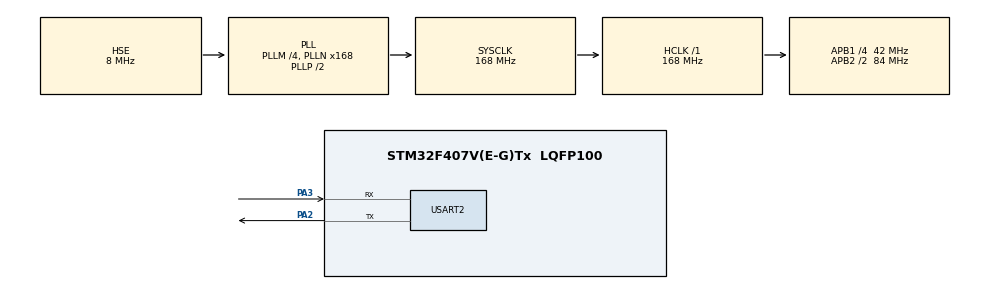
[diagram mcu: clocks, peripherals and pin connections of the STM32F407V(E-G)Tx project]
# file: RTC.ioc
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Mcu.Family=STM32F4
Mcu.Name=STM32F407V(E-G)Tx
Mcu.Package=LQFP100
NVIC.PriorityGroup=NVIC_PRIORITYGROUP_4
NVIC.RTC_Alarm_IRQn=true\:0\:0\:false\:false\:true\:true\:true
PA13.Mode=Serial_Wire
PA13.Signal=SYS_JTMS-SWDIO
PA14.Mode=Serial_Wire
PA14.Signal=SYS_JTCK-SWCLK
PA2.Mode=Asynchronous
PA2.Signal=USART2_TX
PA3.Mode=Asynchronous
PA3.Signal=USART2_RX
PC14-OSC32_IN.Mode=LSE-External-Oscillator
PC14-OSC32_IN.Signal=RCC_OSC32_IN
PC15-OSC32_OUT.Mode=LSE-External-Oscillator
PC15-OSC32_OUT.Signal=RCC_OSC32_OUT
PH0-OSC_IN.Mode=HSE-External-Oscillator
PH0-OSC_IN.Signal=RCC_OSC_IN
PH1-OSC_OUT.Mode=HSE-External-Oscillator
PH1-OSC_OUT.Signal=RCC_OSC_OUT
ProjectManager.HeapSize=0x200
ProjectManager.StackSize=0x400
ProjectManager.TargetToolchain=STM32CubeIDE
RCC.48MHZClocksFreq_Value=84000000
RCC.AHBFreq_Value=168000000
RCC.APB1CLKDivider=RCC_HCLK_DIV4
RCC.APB1Freq_Value=42000000
RCC.APB1TimFreq_Value=84000000
RCC.APB2CLKDivider=RCC_HCLK_DIV2
RCC.APB2Freq_Value=84000000
RCC.APB2TimFreq_Value=168000000
RCC.CortexFreq_Value=168000000
RCC.HCLKFreq_Value=168000000
RCC.HSE_VALUE=8000000
RCC.HSI_VALUE=16000000
RCC.PLLM=4
RCC.PLLN=168
RCC.PLLSourceVirtual=RCC_PLLSOURCE_HSE
RCC.SYSCLKFreq_VALUE=168000000
RCC.SYSCLKSource=RCC_SYSCLKSOURCE_PLLCLK
RCC.VCOOutputFreq_Value=336000000
RTC.Alarm=RTC_ALARM_A
RTC.AlarmMaskDateWeekDay=RTC_ALARMMASK_DATEWEEKDAY
RTC.AsynchPrediv=127
RTC.Date=21
RTC.Format=RTC_FORMAT_BIN
RTC.Hours=18
RTC.Hours_A=18
RTC.Minutes=15
RTC.Minutes_A=16
RTC.Month=RTC_MONTH_OCTOBER
RTC.Seconds=50
RTC.Seconds_A=5
RTC.SynchPrediv=256
RTC.WeekDay=RTC_WEEKDAY_THURSDAY
RTC.Year=21
USART2.VirtualMode=VM_ASYNC
VP_RTC_VS_RTC_Activate.Mode=RTC_Enabled
VP_RTC_VS_RTC_Alarm_A_Intern.Mode=Alarm A
VP_RTC_VS_RTC_Calendar.Mode=RTC_Calendar
board=custom

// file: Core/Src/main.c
/* USER CODE BEGIN Header */
/**
  ******************************************************************************
  * @file           : main.c
  * @brief          : Main program body
  ******************************************************************************
  * @attention
  *
  * <h2><center>&copy; Copyright (c) 2021 STMicroelectronics.
  * All rights reserved.</center></h2>
  *
  * This software component is licensed by ST under BSD 3-Clause license,
  * the "License"; You may not use this file except in compliance with the
  * License. You may obtain a copy of the License at:
  *                        opensource.org/licenses/BSD-3-Clause
  *
  ******************************************************************************
  */
/* USER CODE END Header */
#include "main.h"

/* USER CODE BEGIN Includes */
#include "stdio.h"
#include "string.h"
/* USER CODE END Includes */

RTC_HandleTypeDef hrtc;

UART_HandleTypeDef huart2;

/* USER CODE BEGIN PV */
RTC_TimeTypeDef sTime = {0};
RTC_DateTypeDef DateToUpdate = {0};
RTC_AlarmTypeDef sAlarm = {0}; // структура будильника

char trans_str[64] = {0,};
/* USER CODE END PV */

void SystemClock_Config(void);
static void MX_GPIO_Init(void);
static void MX_RTC_Init(void);
static void MX_USART2_UART_Init(void);

/* USER CODE BEGIN 0 */
void HAL_RTC_AlarmAEventCallback(RTC_HandleTypeDef *hrtc)
{
        snprintf(trans_str, 63, "Alarm_A\n");
        HAL_UART_Transmit(&huart2, (uint8_t*)trans_str, strlen(trans_str), 1000);
}
/* USER CODE END 0 */

int main(void)
{

  /* MCU Configuration--------------------------------------------------------*/

  /* Reset of all peripherals, Initializes the Flash interface and the Systick. */
  HAL_Init();

  /* Configure the system clock */
  SystemClock_Config();

  /* Initialize all configured peripherals */
  MX_GPIO_Init();
  MX_RTC_Init();
  MX_USART2_UART_Init();

  /* Infinite loop */
  while (1)
  {

    /* USER CODE BEGIN 3 */
      HAL_RTC_GetTime(&hrtc, &sTime, RTC_FORMAT_BIN); // RTC_FORMAT_BIN , RTC_FORMAT_BCD
      snprintf(trans_str, 63, "Time %d:%d:%d\n", sTime.Hours, sTime.Minutes, sTime.Seconds);
      //snprintf(trans_str, 63, "Time %d:%d:%d:%lu\n", sTime.Hours, sTime.Minutes, sTime.Seconds, sTime.SubSeconds);
      HAL_UART_Transmit(&huart2, (uint8_t*)trans_str, strlen(trans_str), 1000);

      HAL_RTC_GetDate(&hrtc, &DateToUpdate, RTC_FORMAT_BIN);
      snprintf(trans_str, 63, "Date %d-%d-20%d\n", DateToUpdate.Date, DateToUpdate.Month, DateToUpdate.Year);
      HAL_UART_Transmit(&huart2, (uint8_t*)trans_str, strlen(trans_str), 1000);

      HAL_RTC_GetAlarm(&hrtc, &sAlarm, RTC_ALARM_A, RTC_FORMAT_BIN);
      snprintf(trans_str, 63, "Settings of alarm %d:%d:%d\n", sAlarm.AlarmTime.Hours, sAlarm.AlarmTime.Minutes, sAlarm.AlarmTime.Seconds);
      HAL_UART_Transmit(&huart2, (uint8_t*)trans_str, strlen(trans_str), 1000);

      HAL_Delay(1000);

  }
  /* USER CODE END 3 */
}

void SystemClock_Config(void)
{
  RCC_OscInitTypeDef RCC_OscInitStruct = {0};
  RCC_ClkInitTypeDef RCC_ClkInitStruct = {0};

  /** Configure the main internal regulator output voltage
  */
  __HAL_RCC_PWR_CLK_ENABLE();
  __HAL_PWR_VOLTAGESCALING_CONFIG(PWR_REGULATOR_VOLTAGE_SCALE1);
  /** Initializes the RCC Oscillators according to the specified parameters
  * in the RCC_OscInitTypeDef structure.
  */
  RCC_OscInitStruct.OscillatorType = RCC_OSCILLATORTYPE_LSI|RCC_OSCILLATORTYPE_HSE;
  RCC_OscInitStruct.HSEState = RCC_HSE_ON;
  RCC_OscInitStruct.LSIState = RCC_LSI_ON;
  RCC_OscInitStruct.PLL.PLLState = RCC_PLL_ON;
  RCC_OscInitStruct.PLL.PLLSource = RCC_PLLSOURCE_HSE;
  RCC_OscInitStruct.PLL.PLLM = 4;
  RCC_OscInitStruct.PLL.PLLN = 168;
  RCC_OscInitStruct.PLL.PLLP = RCC_PLLP_DIV2;
  RCC_OscInitStruct.PLL.PLLQ = 4;
  if (HAL_RCC_OscConfig(&RCC_OscInitStruct) != HAL_OK)
  {
    Error_Handler();
  }
  /** Initializes the CPU, AHB and APB buses clocks
  */
  RCC_ClkInitStruct.ClockType = RCC_CLOCKTYPE_HCLK|RCC_CLOCKTYPE_SYSCLK
                              |RCC_CLOCKTYPE_PCLK1|RCC_CLOCKTYPE_PCLK2;
  RCC_ClkInitStruct.SYSCLKSource = RCC_SYSCLKSOURCE_PLLCLK;
  RCC_ClkInitStruct.AHBCLKDivider = RCC_SYSCLK_DIV1;
  RCC_ClkInitStruct.APB1CLKDivider = RCC_HCLK_DIV4;
  RCC_ClkInitStruct.APB2CLKDivider = RCC_HCLK_DIV2;

  if (HAL_RCC_ClockConfig(&RCC_ClkInitStruct, FLASH_LATENCY_5) != HAL_OK)
  {
    Error_Handler();
  }
}

static void MX_RTC_Init(void)
{

  RTC_TimeTypeDef sTime = {0};
  RTC_DateTypeDef sDate = {0};
  RTC_AlarmTypeDef sAlarm = {0};

  /** Initialize RTC Only
  */
  hrtc.Instance = RTC;
  hrtc.Init.HourFormat = RTC_HOURFORMAT_24;
  hrtc.Init.AsynchPrediv = 127;
  hrtc.Init.SynchPrediv = 256;
  hrtc.Init.OutPut = RTC_OUTPUT_DISABLE;
  hrtc.Init.OutPutPolarity = RTC_OUTPUT_POLARITY_HIGH;
  hrtc.Init.OutPutType = RTC_OUTPUT_TYPE_OPENDRAIN;
  if (HAL_RTC_Init(&hrtc) != HAL_OK)
  {
    Error_Handler();
  }

  /** Initialize RTC and set the Time and Date
  */
  sTime.Hours = 18;
  sTime.Minutes = 15;
  sTime.Seconds = 50;
  sTime.DayLightSaving = RTC_DAYLIGHTSAVING_NONE;
  sTime.StoreOperation = RTC_STOREOPERATION_RESET;
  if (HAL_RTC_SetTime(&hrtc, &sTime, RTC_FORMAT_BIN) != HAL_OK)
  {
    Error_Handler();
  }
  sDate.WeekDay = RTC_WEEKDAY_THURSDAY;
  sDate.Month = RTC_MONTH_OCTOBER;
  sDate.Date = 21;
  sDate.Year = 21;

  if (HAL_RTC_SetDate(&hrtc, &sDate, RTC_FORMAT_BIN) != HAL_OK)
  {
    Error_Handler();
  }
  /** Enable the Alarm A
  */
  sAlarm.AlarmTime.Hours = 18;
  sAlarm.AlarmTime.Minutes = 16;
  sAlarm.AlarmTime.Seconds = 5;
  sAlarm.AlarmTime.SubSeconds = 0;
  sAlarm.AlarmTime.DayLightSaving = RTC_DAYLIGHTSAVING_NONE;
  sAlarm.AlarmTime.StoreOperation = RTC_STOREOPERATION_RESET;
  sAlarm.AlarmMask = RTC_ALARMMASK_DATEWEEKDAY;
  sAlarm.AlarmSubSecondMask = RTC_ALARMSUBSECONDMASK_ALL;
  sAlarm.AlarmDateWeekDaySel = RTC_ALARMDATEWEEKDAYSEL_DATE;
  sAlarm.AlarmDateWeekDay = 1;
  sAlarm.Alarm = RTC_ALARM_A;
  if (HAL_RTC_SetAlarm_IT(&hrtc, &sAlarm, RTC_FORMAT_BIN) != HAL_OK)
  {
    Error_Handler();
  }

}

static void MX_USART2_UART_Init(void)
{

  huart2.Instance = USART2;
  huart2.Init.BaudRate = 115200;
  huart2.Init.WordLength = UART_WORDLENGTH_8B;
  huart2.Init.StopBits = UART_STOPBITS_1;
  huart2.Init.Parity = UART_PARITY_NONE;
  huart2.Init.Mode = UART_MODE_TX_RX;
  huart2.Init.HwFlowCtl = UART_HWCONTROL_NONE;
  huart2.Init.OverSampling = UART_OVERSAMPLING_16;
  if (HAL_UART_Init(&huart2) != HAL_OK)
  {
    Error_Handler();
  }

}

static void MX_GPIO_Init(void)
{

  /* GPIO Ports Clock Enable */
  __HAL_RCC_GPIOC_CLK_ENABLE();
  __HAL_RCC_GPIOH_CLK_ENABLE();
  __HAL_RCC_GPIOA_CLK_ENABLE();

}

void Error_Handler(void)
{
  __disable_irq();
  while (1)
  {
  }
}

/************************ (C) COPYRIGHT STMicroelectronics *****END OF FILE****/
